VERSION ""

NS_ :

BS_:

BU_: ECU PowerNode1 PowerNode2 AnalogNode1 AnalogNode2 DashBoard

BO_ 3221225472 VECTOR__INDEPENDENT_SIG_MSG: 0 Vector__XXX
 SG_ Select : 7|8@0+ (1,0) [0|0] "" Vector__XXX
 SG_ NewSignal_0001 : 15|8@0+ (1,0) [0|0] "" Vector__XXX
 SG_ NewSignal_0002 : 0|8@1+ (1,0) [0|0] "" Vector__XXX

BO_ 25 Over_Current_PN1: 2 PowerNode1

BO_ 23 Under_Current_PN1: 2 PowerNode1

BO_ 24 Warning_Current_PN1: 2 PowerNode1

BO_ 28 Over_Current_PN2: 2 PowerNode2

BO_ 27 Under_Current_PN2: 2 PowerNode2

BO_ 26 Warning_Current_PN2: 2 PowerNode2

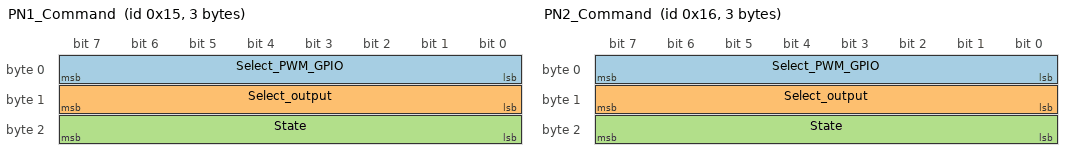
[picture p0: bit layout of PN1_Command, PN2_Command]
BO_ 21 PN1_Command: 3 ECU
 SG_ Select_PWM_GPIO : 0|8@1+ (1,0) [0|0] "" Vector__XXX
 SG_ Select_output : 8|8@1+ (1,0) [0|0] "" Vector__XXX
 SG_ State : 16|8@1+ (1,0) [0|0] "" Vector__XXX

BO_ 22 PN2_Command: 3 ECU
 SG_ Select_PWM_GPIO : 0|8@1+ (1,0) [0|0] "" Vector__XXX
 SG_ Select_output : 8|8@1+ (1,0) [0|0] "" Vector__XXX
 SG_ State : 16|8@1+ (1,0) [0|0] "" Vector__XXX

BO_ 1 APPS1: 2 AnalogNode1
 SG_ Value : 0|16@1+ (1,0) [0|0] "" Vector__XXX

BO_ 2 APPS2: 2 AnalogNode1
 SG_ Value : 0|16@1+ (1,0) [0|0] "" Vector__XXX

BO_ 3 BPPS: 2 AnalogNode1
 SG_ Value : 0|16@1+ (1,0) [0|0] "" Vector__XXX

BO_ 4 BrakeFront: 2 AnalogNode1
 SG_ Value : 0|16@1+ (1,0) [0|0] "" Vector__XXX

BO_ 5 BrakeRear: 2 AnalogNode2
 SG_ Value : 0|16@1+ (1,0) [0|0] "" Vector__XXX

BO_ 7 WaterLevel: 2 AnalogNode2
 SG_ Value : 0|16@1+ (1,0) [0|0] "" Vector__XXX

BO_ 9 HeavesRear: 2 AnalogNode2
 SG_ Value : 0|16@1+ (1,0) [0|0] "" Vector__XXX

BO_ 10 Rolls1: 2 AnalogNode1
 SG_ Value : 0|16@1+ (1,0) [0|0] "" Vector__XXX

BO_ 11 Rolls2: 2 AnalogNode2
 SG_ Value : 0|16@1+ (1,0) [0|0] "" Vector__XXX

BO_ 8 HeavesFront: 2 AnalogNode1
 SG_ Value : 0|16@1+ (1,0) [0|0] "" Vector__XXX

BO_ 6 Steering_Angle: 2 AnalogNode1
 SG_ Value : 0|16@1+ (1,0) [0|0] "" Vector__XXX

BO_ 160 Entering_Idle_State: 1 ECU

BO_ 161 TS_OFF: 1 ECU

BO_ 162 TS_BAD: 1 ECU

BO_ 163 Critical_Error: 1 ECU

BO_ 164 Ready_to_enable_TS: 1 ECU

BO_ 165 TS_Activation_Req_Ready: 1 ECU

BO_ 166 TS_Activation_Req_NReady: 1 ECU

BO_ 167 Entering_Startup_State: 1 ECU

BO_ 168 BMS_Fail: 1 ECU

BO_ 169 IVT_Fail: 1 ECU

BO_ 170 Readyness_Power_Fail: 1 ECU

BO_ 171 Entering_Readyness_Check_State: 1 ECU

BO_ 172 Errorplace_too_many_loops: 1 ECU

BO_ 173 Entering_PreOperational_State: 1 ECU

BO_ 174 Power_request: 1 ECU

BO_ 175 Power_off_to_inverters_req: 1 ECU

BO_ 176 Start_Pressed: 1 ECU

BO_ 177 RDTM_Pressed: 1 ECU

BO_ 178 Entering_RDTM_State: 1 ECU

BO_ 179 RTDM_TA: 1 ECU

BO_ 180 Dissabling_Regen: 1 ECU

BO_ 181 Entering_TS_Active_State: 1 ECU

BO_ 182 TS_LoV: 1 ECU

BO_ 183 TS_On: 1 ECU

BO_ 184 RDTM_Activation_with_no_braking: 1 ECU

BO_ 185 Waiting_Precharge: 1 ECU

BO_ 186 Idle_State_Req: 1 ECU

BO_ 187 Entering_Error_State: 1 ECU

BO_ 12 BTN1: 2 AnalogNode1
 SG_ Value : 0|16@1+ (1,0) [0|0] "" Vector__XXX

BO_ 13 BTN2: 2 AnalogNode1
 SG_ Value : 0|16@1+ (1,0) [0|0] "" Vector__XXX

BO_ 14 BTN3: 2 AnalogNode1
 SG_ Value : 0|16@1+ (1,0) [0|0] "" Vector__XXX

BO_ 29 PN1_Device_Status: 1 PowerNode1

BO_ 30 PN2_Device_Status: 1 PowerNode2

BO_ 31 Start_Calibration: 2 ECU
 SG_ Device : 0|8@1+ (1,0) [0|0] "" Vector__XXX
 SG_ Calib_max_min : 8|8@1+ (1,0) [0|0] "" Vector__XXX

BO_ 32 Calibration_Done: 2 AnalogNode1
 SG_ Device : 0|8@1+ (1,0) [0|0] "" Vector__XXX
 SG_ Calib_max_min : 8|8@1+ (1,0) [0|0] "" Vector__XXX

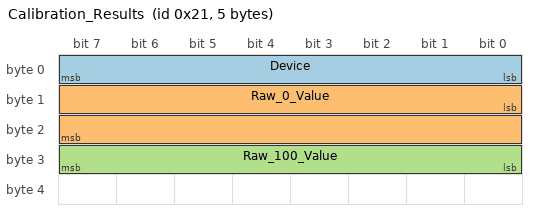
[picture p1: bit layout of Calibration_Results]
BO_ 33 Calibration_Results: 5 AnalogNode1
 SG_ Device : 0|8@1+ (1,0) [0|0] "" Vector__XXX
 SG_ Raw_0_Value : 8|16@1+ (1,0) [0|0] "" Vector__XXX
 SG_ Raw_100_Value : 24|8@1+ (1,0) [0|0] "" Vector__XXX

BO_ 100 Config: 4 Vector__XXX
